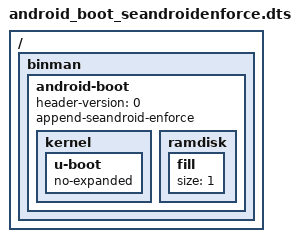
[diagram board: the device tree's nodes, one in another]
// SPDX-License-Identifier: GPL-2.0+
/dts-v1/;
/ {
	#address-cells = <1>;
	#size-cells = <1>;
	binman {
		android-boot {
			header-version = <0>;
			append-seandroid-enforce;
			kernel {
				u-boot {
					no-expanded;
				};
			};
			ramdisk {
				fill {
					size = <1>;
				};
			};
		};
	};
};
